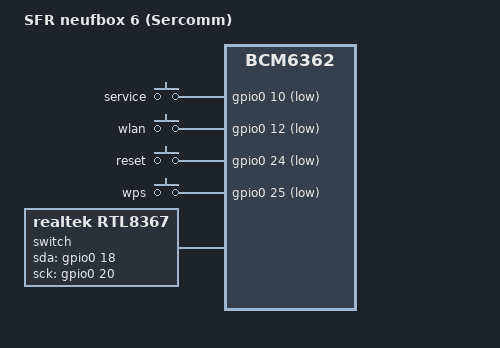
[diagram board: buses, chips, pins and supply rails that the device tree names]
/dts-v1/;

#include "bcm6362.dtsi"

#include <dt-bindings/input/input.h>

/ {
	model = "SFR neufbox 6 (Sercomm)";
	compatible = "sfr,nb6-ser-r0", "brcm,bcm6362";

	chosen {
		bootargs = "root=/dev/mtdblock2 rootfstype=squashfs,jffs2 noinitrd console=ttyS0,115200";
	};

	gpio-keys-polled {
		compatible = "gpio-keys-polled";
		#address-cells = <1>;
		#size-cells = <0>;
		poll-interval = <20>;
		debounce-interval = <60>;

		service {
			label = "service";
			gpios = <&gpio0 10 1>;
			linux,code = <BTN_0>;
		};
		wlan {
			label = "wlan";
			gpios = <&gpio0 12 1>;
			linux,code = <KEY_WLAN>;
		};
		reset {
			label = "reset";
			gpios = <&gpio0 24 1>;
			linux,code = <KEY_RESTART>;
		};
		wps {
			label = "wps";
			gpios = <&gpio0 25 1>;
			linux,code = <KEY_WPS_BUTTON>;
		};
	};

	switch {
		compatible = "realtek,rtl8367";
		gpio-sda = <&gpio0 18 0>;
		gpio-sck = <&gpio0 20 0>;

		realtek,extif0 = <1 5 1 1 1 1 1 1 2>;
	};
};
